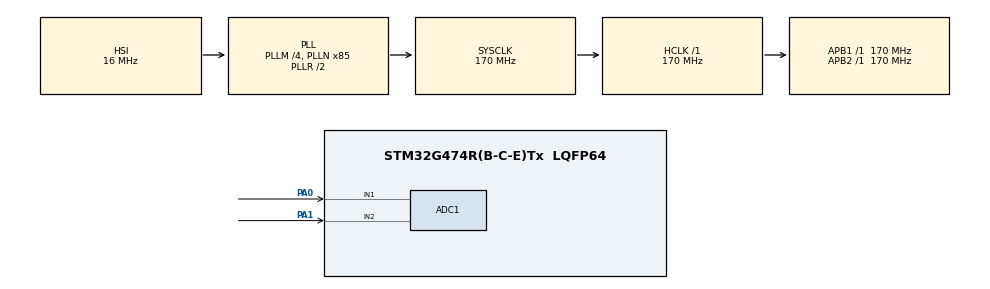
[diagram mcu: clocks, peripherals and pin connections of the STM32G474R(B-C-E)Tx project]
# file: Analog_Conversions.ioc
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ADC1.Channel-0\#ChannelRegularConversion=ADC_CHANNEL_1
ADC1.Channel-1\#ChannelRegularConversion=ADC_CHANNEL_2
ADC1.ContinuousConvMode=DISABLE
ADC1.DMAContinuousRequests=ENABLE
ADC1.EOCSelection=ADC_EOC_SINGLE_CONV
ADC1.ExternalTrigConv=ADC_EXTERNALTRIG_T3_TRGO
ADC1.LowPowerAutoWait=DISABLE
ADC1.NbrOfConversion=2
ADC1.NbrOfConversionFlag=1
ADC1.OffsetNumber-0\#ChannelRegularConversion=ADC_OFFSET_NONE
ADC1.OffsetNumber-1\#ChannelRegularConversion=ADC_OFFSET_NONE
ADC1.Rank-0\#ChannelRegularConversion=1
ADC1.Rank-1\#ChannelRegularConversion=2
ADC1.SamplingTime-0\#ChannelRegularConversion=ADC_SAMPLETIME_47CYCLES_5
ADC1.SamplingTime-1\#ChannelRegularConversion=ADC_SAMPLETIME_47CYCLES_5
ADC1.master=1
Dma.ADC1.0.Direction=DMA_PERIPH_TO_MEMORY
Dma.ADC1.0.EventEnable=DISABLE
Dma.ADC1.0.Instance=DMA1_Channel1
Dma.ADC1.0.MemDataAlignment=DMA_MDATAALIGN_HALFWORD
Dma.ADC1.0.MemInc=DMA_MINC_ENABLE
Dma.ADC1.0.Mode=DMA_CIRCULAR
Dma.ADC1.0.PeriphDataAlignment=DMA_PDATAALIGN_HALFWORD
Dma.ADC1.0.PeriphInc=DMA_PINC_DISABLE
Dma.ADC1.0.Polarity=HAL_DMAMUX_REQ_GEN_RISING
Dma.ADC1.0.Priority=DMA_PRIORITY_LOW
Dma.ADC1.0.RequestNumber=1
Dma.ADC1.0.SignalID=NONE
Dma.ADC1.0.SyncEnable=DISABLE
Dma.ADC1.0.SyncPolarity=HAL_DMAMUX_SYNC_NO_EVENT
Dma.ADC1.0.SyncRequestNumber=1
Dma.ADC1.0.SyncSignalID=NONE
Dma.Request0=ADC1
Mcu.Family=STM32G4
Mcu.Name=STM32G474R(B-C-E)Tx
Mcu.Package=LQFP64
NVIC.DMA1_Channel1_IRQn=true\:0\:0\:false\:false\:true\:false\:true
NVIC.PriorityGroup=NVIC_PRIORITYGROUP_4
PA0.Mode=IN1-Single-Ended
PA0.Signal=ADC1_IN1
PA1.Mode=IN2-Single-Ended
PA1.Signal=ADC1_IN2
PA13.Mode=Serial_Wire
PA13.Signal=SYS_JTMS-SWDIO
PA14.Mode=Serial_Wire
PA14.Signal=SYS_JTCK-SWCLK
ProjectManager.HeapSize=0x200
ProjectManager.StackSize=0x400
ProjectManager.TargetToolchain=STM32CubeIDE
RCC.ADC12Freq_Value=170000000
RCC.ADC345Freq_Value=170000000
RCC.AHBFreq_Value=170000000
RCC.APB1Freq_Value=170000000
RCC.APB1TimFreq_Value=170000000
RCC.APB2Freq_Value=170000000
RCC.APB2TimFreq_Value=170000000
RCC.CortexFreq_Value=170000000
RCC.EXTERNAL_CLOCK_VALUE=12288000
RCC.HCLKFreq_Value=170000000
RCC.HSE_VALUE=24000000
RCC.HSI48_VALUE=48000000
RCC.HSI_VALUE=16000000
RCC.LSE_VALUE=32768
RCC.PLLM=RCC_PLLM_DIV4
RCC.PLLN=85
RCC.RTCClockSelection=RCC_RTCCLKSOURCE_LSE
RCC.SYSCLKFreq_VALUE=170000000
RCC.SYSCLKSource=RCC_SYSCLKSOURCE_PLLCLK
RCC.USBFreq_Value=170000000
RCC.VCOOutputFreq_Value=340000000
TIM3.PeriodNoDither=999
TIM3.Prescaler=63999
TIM3.TIM_MasterOutputTrigger=TIM_TRGO_UPDATE
VP_SYS_VS_DBSignals.Mode=DisableDeadBatterySignals
VP_TIM3_VS_ClockSourceINT.Mode=Internal
board=NUCLEO-G474RE

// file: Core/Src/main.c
/* USER CODE BEGIN Header */
/**
  ******************************************************************************
  * @file           : main.c
  * @brief          : Main program body
  ******************************************************************************
  * @attention
  *
  * <h2><center>&copy; Copyright (c) 2020 STMicroelectronics.
  * All rights reserved.</center></h2>
  *
  * This software component is licensed by ST under BSD 3-Clause license,
  * the "License"; You may not use this file except in compliance with the
  * License. You may obtain a copy of the License at:
  *                        opensource.org/licenses/BSD-3-Clause
  *
  ******************************************************************************
  */
/* USER CODE END Header */

#include "main.h"

/* USER CODE BEGIN Includes */
#include <math.h>
/* USER CODE END Includes */

ADC_HandleTypeDef hadc1;
DMA_HandleTypeDef hdma_adc1;

TIM_HandleTypeDef htim3;

/* USER CODE BEGIN PV */
volatile uint8_t convCompleted = 0;
/* USER CODE END PV */

void SystemClock_Config(void);
static void MX_GPIO_Init(void);
static void MX_DMA_Init(void);
static void MX_ADC1_Init(void);
static void MX_TIM3_Init(void);

int main(void)
{

  /* MCU Configuration--------------------------------------------------------*/

  /* Reset of all peripherals, Initializes the Flash interface and the Systick. */
  HAL_Init();

  /* Configure the system clock */
  SystemClock_Config();

  /* Initialize all configured peripherals */
  MX_GPIO_Init();
  MX_DMA_Init();
  MX_ADC1_Init();
  MX_TIM3_Init();
  /* USER CODE BEGIN 2 */
  uint16_t rawValues[3];
  int value1=0;
  int value2=0;

  HAL_ADCEx_Calibration_Start(&hadc1,ADC_SINGLE_ENDED);
  HAL_TIM_Base_Start(&htim3);
  HAL_ADC_Start_DMA(&hadc1,(uint32_t*)rawValues, 2);
  /* USER CODE END 2 */

  /* Infinite loop */
  while (1)
  {

    /* USER CODE BEGIN 3 */
	  while(!convCompleted);
	  value1=rawValues[0];
	  value2=rawValues[1];

	  // THE COMMENTED CODE SHOULD COMPUTE THE TEMPERATURE FROM TH VOLTAGE READINGS OF THE NTC (NOT CHECKED YET)

	  //V_sign[0]=((float)rawValues[0]) / 4095 * 3.3;
	  //Res[0]=(V_plus-V_sign[0])*R_circ/V_sign[0];

	  //V_sign[1]=((float)rawValues[1]) / 4095 * 3.3;
	  //Res[1]=(V_plus-V_sign[1])*R_circ/V_sign[1];

	  // CONVERSION OF NTC RESISTANCE INTO TEMPERATURE
	  //inv_T[0]=(1/T0)+(1/beta)*log(Res[0]/R0);
	  //Temp.Temp_0=(1/inv_T[0]);
	  //inv_T[1]=(1/T0)+(1/beta)*log(Res[1]/R0);
	  //Temp.Temp_1=(1/inv_T[0]);

  }
  /* USER CODE END 3 */
}

void SystemClock_Config(void)
{
  RCC_OscInitTypeDef RCC_OscInitStruct = {0};
  RCC_ClkInitTypeDef RCC_ClkInitStruct = {0};
  RCC_PeriphCLKInitTypeDef PeriphClkInit = {0};

  /** Configure the main internal regulator output voltage
  */
  HAL_PWREx_ControlVoltageScaling(PWR_REGULATOR_VOLTAGE_SCALE1_BOOST);
  /** Initializes the CPU, AHB and APB busses clocks
  */
  RCC_OscInitStruct.OscillatorType = RCC_OSCILLATORTYPE_HSI;
  RCC_OscInitStruct.HSIState = RCC_HSI_ON;
  RCC_OscInitStruct.HSICalibrationValue = RCC_HSICALIBRATION_DEFAULT;
  RCC_OscInitStruct.PLL.PLLState = RCC_PLL_ON;
  RCC_OscInitStruct.PLL.PLLSource = RCC_PLLSOURCE_HSI;
  RCC_OscInitStruct.PLL.PLLM = RCC_PLLM_DIV4;
  RCC_OscInitStruct.PLL.PLLN = 85;
  RCC_OscInitStruct.PLL.PLLP = RCC_PLLP_DIV2;
  RCC_OscInitStruct.PLL.PLLQ = RCC_PLLQ_DIV2;
  RCC_OscInitStruct.PLL.PLLR = RCC_PLLR_DIV2;
  if (HAL_RCC_OscConfig(&RCC_OscInitStruct) != HAL_OK)
  {
    Error_Handler();
  }
  /** Initializes the CPU, AHB and APB busses clocks
  */
  RCC_ClkInitStruct.ClockType = RCC_CLOCKTYPE_HCLK|RCC_CLOCKTYPE_SYSCLK
                              |RCC_CLOCKTYPE_PCLK1|RCC_CLOCKTYPE_PCLK2;
  RCC_ClkInitStruct.SYSCLKSource = RCC_SYSCLKSOURCE_PLLCLK;
  RCC_ClkInitStruct.AHBCLKDivider = RCC_SYSCLK_DIV1;
  RCC_ClkInitStruct.APB1CLKDivider = RCC_HCLK_DIV1;
  RCC_ClkInitStruct.APB2CLKDivider = RCC_HCLK_DIV1;

  if (HAL_RCC_ClockConfig(&RCC_ClkInitStruct, FLASH_LATENCY_8) != HAL_OK)
  {
    Error_Handler();
  }
  /** Initializes the peripherals clocks
  */
  PeriphClkInit.PeriphClockSelection = RCC_PERIPHCLK_ADC12;
  PeriphClkInit.Adc12ClockSelection = RCC_ADC12CLKSOURCE_SYSCLK;
  if (HAL_RCCEx_PeriphCLKConfig(&PeriphClkInit) != HAL_OK)
  {
    Error_Handler();
  }
}

static void MX_ADC1_Init(void)
{

  ADC_MultiModeTypeDef multimode = {0};
  ADC_ChannelConfTypeDef sConfig = {0};

  /** Common config
  */
  hadc1.Instance = ADC1;
  hadc1.Init.ClockPrescaler = ADC_CLOCK_ASYNC_DIV1;
  hadc1.Init.Resolution = ADC_RESOLUTION_12B;
  hadc1.Init.DataAlign = ADC_DATAALIGN_RIGHT;
  hadc1.Init.GainCompensation = 0;
  hadc1.Init.ScanConvMode = ADC_SCAN_ENABLE;
  hadc1.Init.EOCSelection = ADC_EOC_SINGLE_CONV;
  hadc1.Init.LowPowerAutoWait = DISABLE;
  hadc1.Init.ContinuousConvMode = DISABLE;
  hadc1.Init.NbrOfConversion = 2;
  hadc1.Init.DiscontinuousConvMode = DISABLE;
  hadc1.Init.ExternalTrigConv = ADC_EXTERNALTRIG_T3_TRGO;
  hadc1.Init.ExternalTrigConvEdge = ADC_EXTERNALTRIGCONVEDGE_RISING;
  hadc1.Init.DMAContinuousRequests = ENABLE;
  hadc1.Init.Overrun = ADC_OVR_DATA_PRESERVED;
  hadc1.Init.OversamplingMode = DISABLE;
  if (HAL_ADC_Init(&hadc1) != HAL_OK)
  {
    Error_Handler();
  }
  /** Configure the ADC multi-mode
  */
  multimode.Mode = ADC_MODE_INDEPENDENT;
  if (HAL_ADCEx_MultiModeConfigChannel(&hadc1, &multimode) != HAL_OK)
  {
    Error_Handler();
  }
  /** Configure Regular Channel
  */
  sConfig.Channel = ADC_CHANNEL_1;
  sConfig.Rank = ADC_REGULAR_RANK_1;
  sConfig.SamplingTime = ADC_SAMPLETIME_47CYCLES_5;
  sConfig.SingleDiff = ADC_SINGLE_ENDED;
  sConfig.OffsetNumber = ADC_OFFSET_NONE;
  sConfig.Offset = 0;
  if (HAL_ADC_ConfigChannel(&hadc1, &sConfig) != HAL_OK)
  {
    Error_Handler();
  }
  /** Configure Regular Channel
  */
  sConfig.Channel = ADC_CHANNEL_2;
  sConfig.Rank = ADC_REGULAR_RANK_2;
  if (HAL_ADC_ConfigChannel(&hadc1, &sConfig) != HAL_OK)
  {
    Error_Handler();
  }

}

static void MX_TIM3_Init(void)
{

  TIM_ClockConfigTypeDef sClockSourceConfig = {0};
  TIM_MasterConfigTypeDef sMasterConfig = {0};

  htim3.Instance = TIM3;
  htim3.Init.Prescaler = 16999;
  htim3.Init.CounterMode = TIM_COUNTERMODE_UP;
  htim3.Init.Period = 999;
  htim3.Init.ClockDivision = TIM_CLOCKDIVISION_DIV1;
  htim3.Init.AutoReloadPreload = TIM_AUTORELOAD_PRELOAD_DISABLE;
  if (HAL_TIM_Base_Init(&htim3) != HAL_OK)
  {
    Error_Handler();
  }
  sClockSourceConfig.ClockSource = TIM_CLOCKSOURCE_INTERNAL;
  if (HAL_TIM_ConfigClockSource(&htim3, &sClockSourceConfig) != HAL_OK)
  {
    Error_Handler();
  }
  sMasterConfig.MasterOutputTrigger = TIM_TRGO_UPDATE;
  sMasterConfig.MasterSlaveMode = TIM_MASTERSLAVEMODE_DISABLE;
  if (HAL_TIMEx_MasterConfigSynchronization(&htim3, &sMasterConfig) != HAL_OK)
  {
    Error_Handler();
  }

}

static void MX_DMA_Init(void)
{

  /* DMA controller clock enable */
  __HAL_RCC_DMAMUX1_CLK_ENABLE();
  __HAL_RCC_DMA1_CLK_ENABLE();

  /* DMA interrupt init */
  /* DMA1_Channel1_IRQn interrupt configuration */
  HAL_NVIC_SetPriority(DMA1_Channel1_IRQn, 0, 0);
  HAL_NVIC_EnableIRQ(DMA1_Channel1_IRQn);

}

static void MX_GPIO_Init(void)
{

  /* GPIO Ports Clock Enable */
  __HAL_RCC_GPIOA_CLK_ENABLE();

}

/* USER CODE BEGIN 4 */
void HAL_ADC_ConvCpltCallback(ADC_HandleTypeDef* hadc)
{
	convCompleted = 1;
}
/* USER CODE END 4 */

void Error_Handler(void)
{
}

/************************ (C) COPYRIGHT STMicroelectronics *****END OF FILE****/
